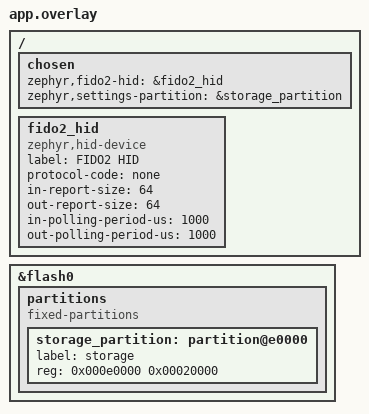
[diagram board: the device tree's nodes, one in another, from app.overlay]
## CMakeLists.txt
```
# SPDX-License-Identifier: Apache-2.0

cmake_minimum_required(VERSION 3.20.0)
find_package(Zephyr REQUIRED HINTS $ENV{ZEPHYR_BASE})
project(fido2)

target_sources(app PRIVATE src/main.c)
```

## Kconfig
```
# Copyright (c) 2026 Siratul Islam <email@sirat.me>
# SPDX-License-Identifier: Apache-2.0

# Source common USB sample options used to initialize new experimental USB
# device stack. The scope of these options is limited to USB samples in project
# tree, you cannot use them in your own application.
source "samples/subsys/usb/common/Kconfig.sample_usbd"

config FIDO2_SAMPLE_STORAGE_SD_CARD
	bool "Use SD card for FIDO2 settings storage"
	select DISK_ACCESS
	select DISK_DRIVERS
	select DISK_DRIVER_SDMMC
	select FAT_FILESYSTEM_ELM
	select FILE_SYSTEM
	select SETTINGS
	help
	  Store FIDO2 credential records and exported ES256 credential keys
	  in a settings file on an SD card. The board must provide a working
	  SDMMC disk-access device whose FatFS drive name matches
	  FIDO2_SAMPLE_STORAGE_SD_CARD_MOUNT_POINT.

config FIDO2_SAMPLE_STORAGE_SD_CARD_MOUNT_POINT
	string "FIDO2 SD card FATFS mount point"
	depends on FIDO2_SAMPLE_STORAGE_SD_CARD
	default "/SD:"
	help
	  FATFS mount point used for the SD card storage backend. This must
	  match the disk-access volume name with a leading slash and trailing
	  colon, for example "/SD:" for CONFIG_SDMMC_VOLUME_NAME="SD".

source "Kconfig.zephyr"
```

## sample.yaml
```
sample:
  name: USB FIDO2 authenticator sample
common:
  depends_on:
    - usbd
  tags:
    - usb
    - fido2
    - authentication
  timeout: 15
  harness: console
  harness_config:
    type: one_line
    regex:
      - "FIDO2 USB HID sample is ready"
  integration_platforms:
    - stm32f4_disco
    - stm32f746g_disco
tests:
  sample.usbd.fido2: {}
```

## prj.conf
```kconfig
CONFIG_USB_DEVICE_STACK=y
CONFIG_USB_DEVICE_HID=y
CONFIG_USB_DEVICE_PRODUCT="Zephyr FIDO2 Sample"
CONFIG_USB_DEVICE_PID=0x0012
CONFIG_USB_DEVICE_INITIALIZE_AT_BOOT=n
CONFIG_ENABLE_HID_INT_OUT_EP=y
CONFIG_HID_INTERRUPT_EP_MPS=64
CONFIG_USB_HID_REPORTS=1

CONFIG_FIDO2=y
CONFIG_FIDO2_TRANSPORT_USB_HID=y
CONFIG_FIDO2_ATTESTATION_SELF=y
CONFIG_FIDO2_PIN_PROTOCOL=n
CONFIG_FIDO2_TEST_USER_VERIFICATION=y

CONFIG_MBEDTLS=y
CONFIG_MBEDTLS_PSA_CRYPTO_C=y
CONFIG_MBEDTLS_ENABLE_HEAP=y
CONFIG_MBEDTLS_HEAP_SIZE=8192

CONFIG_LOG=y
CONFIG_TEST_RANDOM_GENERATOR=y
CONFIG_MAIN_STACK_SIZE=4096
CONFIG_FIDO2_LOG_LEVEL_INF=y
CONFIG_USB_DRIVER_LOG_LEVEL_WRN=y
CONFIG_USB_DEVICE_LOG_LEVEL_WRN=y
CONFIG_USB_HID_LOG_LEVEL_WRN=y
```

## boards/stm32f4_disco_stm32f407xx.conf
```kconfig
CONFIG_FIDO2_STORAGE_SETTINGS=y

CONFIG_FLASH=y
CONFIG_FLASH_MAP=y
CONFIG_ZMS=y
CONFIG_SETTINGS=y
CONFIG_SETTINGS_ZMS=y
CONFIG_SETTINGS_ZMS_FORCE_MOUNT=y
CONFIG_SECURE_STORAGE_ITS_STORE_IMPLEMENTATION_SETTINGS=y
```

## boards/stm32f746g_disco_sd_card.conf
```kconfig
# SPDX-License-Identifier: Apache-2.0

CONFIG_FIDO2_SAMPLE_STORAGE_SD_CARD=y
CONFIG_FIDO2_SAMPLE_STORAGE_SD_CARD_MOUNT_POINT="/SD:"

CONFIG_SETTINGS_FILE=y
CONFIG_SETTINGS_FILE_PATH="/SD:/FIDO2.SET"
CONFIG_SETTINGS_FILE_MAX_LINES=64

# Format the card automatically if no FAT filesystem is found on mount.
CONFIG_FILE_SYSTEM_MKFS=y
CONFIG_FS_FATFS_MOUNT_MKFS=y
```

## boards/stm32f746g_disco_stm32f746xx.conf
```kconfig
CONFIG_FIDO2_STORAGE_SETTINGS=y

CONFIG_FLASH=y
CONFIG_FLASH_MAP=y
CONFIG_FCB=y
CONFIG_SETTINGS=y
CONFIG_SETTINGS_FCB=y
```

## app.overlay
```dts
/*
 * Copyright (c) 2026 Siratul Islam <email@sirat.me>
 *
 * SPDX-License-Identifier: Apache-2.0
 */

/ {
	chosen {
		zephyr,fido2-hid = &fido2_hid;
		zephyr,settings-partition = &storage_partition;
	};

	fido2_hid: fido2_hid {
		compatible = "zephyr,hid-device";
		label = "FIDO2 HID";
		protocol-code = "none";
		in-report-size = <64>;
		out-report-size = <64>;
		in-polling-period-us = <1000>;
		out-polling-period-us = <1000>;
	};
};

&flash0 {
	partitions {
		compatible = "fixed-partitions";
		#address-cells = <1>;
		#size-cells = <1>;

		storage_partition: partition@e0000 {
			label = "storage";
			reg = <0x000e0000 0x00020000>;
		};
	};
};
```

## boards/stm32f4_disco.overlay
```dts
/*
 * Copyright (c) 2026 Siratul Islam <email@sirat.me>
 *
 * SPDX-License-Identifier: Apache-2.0
 */

/ {
	chosen {
		zephyr,code-partition = &slot0_partition;
		zephyr,settings-partition = &storage_partition;
	};
};

&flash0 {
	partitions {
		compatible = "fixed-partitions";
		#address-cells = <1>;
		#size-cells = <1>;

		slot0_partition: partition@0 {
			label = "image-0";
			reg = <0x00000000 0x000c0000>;
		};

		storage_partition: partition@c0000 {
			label = "storage";
			reg = <0x000c0000 0x00040000>;
		};
	};
};
```

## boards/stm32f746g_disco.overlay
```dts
/*
 * Copyright (c) 2026 Siratul Islam <email@sirat.me>
 *
 * SPDX-License-Identifier: Apache-2.0
 */

/ {
	chosen {
		zephyr,code-partition = &slot0_partition;
		zephyr,settings-partition = &fido2_storage_partition;
	};
};

&flash0 {
	partitions {
		compatible = "fixed-partitions";
		#address-cells = <1>;
		#size-cells = <1>;

		slot0_partition: partition@0 {
			label = "image-0";
			reg = <0x00000000 0x00080000>;
		};

		fido2_storage_partition: partition@80000 {
			label = "fido2-storage";
			reg = <0x00080000 0x00080000>;
		};
	};
};
```

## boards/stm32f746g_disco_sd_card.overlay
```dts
/*
 * SPDX-License-Identifier: Apache-2.0
 */

/ {
	fstab {
		compatible = "zephyr,fstab";

		fido2_sd_card: fido2_sd_card {
			compatible = "zephyr,fstab,fatfs";
			automount;
			disk-access;
			mount-point = "/SD:";
		};
	};
};
```

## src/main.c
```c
/*
 * Copyright (c) 2026 Siratul Islam <email@sirat.me>
 *
 * SPDX-License-Identifier: Apache-2.0
 */

#include <zephyr/authentication/fido2/fido2.h>
#include <zephyr/fs/fs.h>
#include <zephyr/kernel.h>
#include <zephyr/logging/log.h>
#include <zephyr/usb/usb_device.h>

#if defined(CONFIG_FIDO2_SAMPLE_STORAGE_SD_CARD)
#include <ff.h>

static FATFS fido2_sd_fs;
static struct fs_mount_t fido2_sd_mount = {
	.type = FS_FATFS,
	.mnt_point = CONFIG_FIDO2_SAMPLE_STORAGE_SD_CARD_MOUNT_POINT,
	.fs_data = &fido2_sd_fs,
};
#endif /* CONFIG_FIDO2_SAMPLE_STORAGE_SD_CARD */

LOG_MODULE_REGISTER(main, LOG_LEVEL_INF);

static void status_cb(enum usb_dc_status_code status, const uint8_t *param)
{
	ARG_UNUSED(param);

	switch (status) {
	case USB_DC_RESET:
		LOG_INF("USB reset");
		break;
	case USB_DC_CONFIGURED:
		LOG_INF("USB configured");
		break;
	default:
		break;
	}
}

#if defined(CONFIG_FIDO2_SAMPLE_STORAGE_SD_CARD)
static int fido2_mount_sd_card(void)
{
	int ret;

	ret = fs_mount(&fido2_sd_mount);
	if (ret) {
		LOG_ERR("Failed to mount FIDO2 SD card storage at %s: %d",
			CONFIG_FIDO2_SAMPLE_STORAGE_SD_CARD_MOUNT_POINT, ret);
		return ret;
	}

	LOG_INF("FIDO2 SD card storage mounted at %s",
		CONFIG_FIDO2_SAMPLE_STORAGE_SD_CARD_MOUNT_POINT);
	return 0;
}
#endif /* CONFIG_FIDO2_SAMPLE_STORAGE_SD_CARD */

int main(void)
{
	int ret;

#if defined(CONFIG_FIDO2_SAMPLE_STORAGE_SD_CARD)
	ret = fido2_mount_sd_card();
	if (ret) {
		return ret;
	}
#endif /* CONFIG_FIDO2_SAMPLE_STORAGE_SD_CARD */

	ret = fido2_init();
	if (ret) {
		LOG_ERR("Failed to initialize FIDO2 subsystem: %d", ret);
		return ret;
	}

	ret = fido2_start();
	if (ret) {
		LOG_ERR("Failed to start FIDO2 authenticator: %d", ret);
		return ret;
	}

	ret = usb_enable(status_cb);
	if (ret) {
		LOG_ERR("Failed to enable USB device support: %d", ret);
		return ret;
	}

	LOG_INF("FIDO2 USB HID sample is ready");

	while (true) {
		k_sleep(K_SECONDS(1));
	}

	return 0;
}
```
